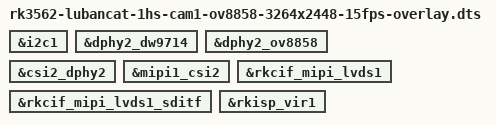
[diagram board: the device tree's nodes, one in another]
/dts-v1/;
/plugin/;

#include <dt-bindings/usb/pd.h>
#include <dt-bindings/gpio/gpio.h>
#include <dt-bindings/pwm/pwm.h>
#include <dt-bindings/pinctrl/rockchip.h>
#include <dt-bindings/input/rk-input.h>
#include <dt-bindings/display/drm_mipi_dsi.h>
#include <dt-bindings/display/rockchip_vop.h>
#include <dt-bindings/sensor-dev.h>

/ {
	fragment@0 {
		target = <&i2c1>;

		__overlay__ {
			status = "okay";
		};
	};

	fragment@1 {
		target = <&dphy2_dw9714>;
		__overlay__ {
			status = "okay";
		};
	};

	fragment@2 {
		target = <&dphy2_ov8858>;
		__overlay__ {
			status = "okay";
		};
	};

	fragment@3 {
		target = <&csi2_dphy2>;
		__overlay__ {
			status = "okay";
		};
	};

	fragment@4 {
		target = <&mipi1_csi2>;
		__overlay__ {
			status = "okay";
		};
	};

	fragment@5 {
		target = <&rkcif_mipi_lvds1>;
		__overlay__ {
			status = "okay";
		};
	};

	fragment@6 {
		target = <&rkcif_mipi_lvds1_sditf>;
		__overlay__ {
			status = "okay";
		};
	};

	fragment@7 {
		target = <&rkisp_vir1>;
		__overlay__ {
			status = "okay";
		};
	};
};
